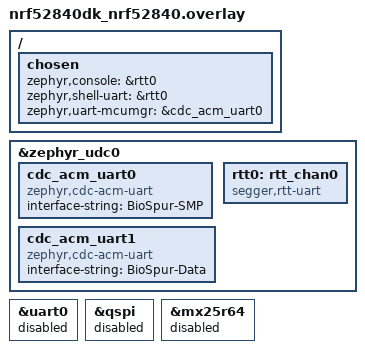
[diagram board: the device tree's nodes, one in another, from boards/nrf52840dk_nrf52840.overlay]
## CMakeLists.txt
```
cmake_minimum_required(VERSION 3.20.0)

find_package(Zephyr REQUIRED HINTS $ENV{ZEPHYR_BASE})
project(central)

target_sources(app PRIVATE
	src/main.c
	src/app_ble.c
	src/cdc_async.c
	src/ota_bridge.c
	src/tsync_master.c
	src/wdt_monitor.c
)

target_compile_definitions(app PRIVATE
	BSGR_CENTRAL_SAFE_BOOT=1
)

target_include_directories(app PRIVATE
	${CMAKE_CURRENT_SOURCE_DIR}/include
	${CMAKE_CURRENT_SOURCE_DIR}/../shared/include
)
```

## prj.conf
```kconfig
CONFIG_BT=y
CONFIG_BT_CENTRAL=y
CONFIG_BT_PERIPHERAL=n
CONFIG_BT_DEVICE_NAME="BSGR_CENTRAL"
CONFIG_BT_SMP=y
CONFIG_BT_PRIVACY=y
CONFIG_BT_BONDABLE=y
CONFIG_BT_SETTINGS=y
CONFIG_BT_GATT_CLIENT=y
CONFIG_BT_GATT_DM=y
CONFIG_BT_DFU_SMP=y
CONFIG_BT_GATT_SERVICE_CHANGED=y
CONFIG_BT_SCAN=y
CONFIG_BT_NUS_CLIENT=y
CONFIG_BT_NUS=n
CONFIG_BT_MAX_CONN=4
CONFIG_BT_MAX_PAIRED=4
CONFIG_BT_CTLR_PHY_2M=y
CONFIG_BT_USER_PHY_UPDATE=y
CONFIG_BT_CTLR_DATA_LENGTH_MAX=251
CONFIG_BT_L2CAP_TX_MTU=247
CONFIG_BT_BUF_ACL_RX_SIZE=251
CONFIG_BT_BUF_ACL_TX_SIZE=251
CONFIG_BT_BUF_ACL_RX_COUNT=16
CONFIG_BT_BUF_ACL_TX_COUNT=16
CONFIG_BT_L2CAP_TX_BUF_COUNT=16
CONFIG_BT_BUF_CMD_TX_COUNT=8
CONFIG_BT_BUF_EVT_RX_SIZE=255
CONFIG_BT_BUF_EVT_RX_COUNT=16

CONFIG_BOOTLOADER_MCUBOOT=y
CONFIG_MCUBOOT_BOOTUTIL_LIB=y
CONFIG_MCUBOOT_IMGTOOL_SIGN_VERSION="0.1.0+1"
CONFIG_FLASH=y
CONFIG_FLASH_PAGE_LAYOUT=y
CONFIG_FLASH_MAP=y
CONFIG_STREAM_FLASH=y
CONFIG_IMG_MANAGER=y
CONFIG_MCUMGR=y
CONFIG_MCUMGR_GRP_IMG=y
CONFIG_MCUMGR_GRP_OS=y
CONFIG_MCUMGR_GRP_OS_BOOTLOADER_INFO=y
CONFIG_MCUMGR_GRP_OS_MCUMGR_PARAMS=y
CONFIG_MCUMGR_TRANSPORT_UART=y
CONFIG_MCUMGR_TRANSPORT_UART_MTU=256
CONFIG_ZCBOR=y
CONFIG_ZCBOR_STOP_ON_ERROR=y
CONFIG_CRC=y
CONFIG_NET_BUF=y
CONFIG_BASE64=y

CONFIG_USB_DEVICE_STACK=y
CONFIG_USB_DEVICE_INITIALIZE_AT_BOOT=y
CONFIG_USB_CDC_ACM=y
CONFIG_USB_DEVICE_MANUFACTURER="BioSpur"
CONFIG_USB_DEVICE_PRODUCT="BioSpur Central"
CONFIG_UART_LINE_CTRL=y
CONFIG_UART_INTERRUPT_DRIVEN=y
CONFIG_SERIAL=y

CONFIG_SETTINGS=y
CONFIG_REBOOT=y
CONFIG_WATCHDOG=y
CONFIG_GPIO=y
CONFIG_ASSERT=y

CONFIG_LOG=y
CONFIG_LOG_DEFAULT_LEVEL=3
CONFIG_LOG_MODE_DEFERRED=y
CONFIG_LOG_BACKEND_RTT=y
CONFIG_LOG_BACKEND_UART=n
CONFIG_USE_SEGGER_RTT=y
CONFIG_RTT_CONSOLE=y
CONFIG_CONSOLE=y
CONFIG_UART_CONSOLE=n
CONFIG_PRINTK=y
CONFIG_SHELL=n

CONFIG_MAIN_STACK_SIZE=4096
CONFIG_SYSTEM_WORKQUEUE_STACK_SIZE=4096
CONFIG_ISR_STACK_SIZE=2048
CONFIG_HEAP_MEM_POOL_SIZE=16384
```

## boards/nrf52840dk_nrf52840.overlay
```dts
/ {
	chosen {
		zephyr,console = &rtt0;
		zephyr,shell-uart = &rtt0;
		/* Logical USB CDC interface 0 is reserved for MCUmgr/SMP. */
		zephyr,uart-mcumgr = &cdc_acm_uart0;
	};
};

&zephyr_udc0 {
	cdc_acm_uart0: cdc_acm_uart0 {
		compatible = "zephyr,cdc-acm-uart";
		/* Interface 0: MCUmgr/SMP control plane. */
		interface-string = "BioSpur-SMP";
		status = "okay";
	};

	cdc_acm_uart1: cdc_acm_uart1 {
		compatible = "zephyr,cdc-acm-uart";
		/* Interface 1: sensor/runtime data plane. */
		interface-string = "BioSpur-Data";
		status = "okay";
	};

	rtt0: rtt_chan0 {
		compatible = "segger,rtt-uart";
		status = "okay";
	};
};

&uart0 {
	status = "disabled";
};

&qspi {
	status = "disabled";
};

&mx25r64 {
	status = "disabled";
};
```

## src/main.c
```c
#include <zephyr/kernel.h>
#include <zephyr/logging/log.h>

#include "app_ble.h"
#include "cdc_async.h"
#include "ota_bridge.h"
#include "tsync_master.h"
#include "wdt_monitor.h"

LOG_MODULE_REGISTER(central_main, LOG_LEVEL_INF);

int main(void)
{
	int err;

	LOG_INF("BSGR Central safe-boot bring-up");

	err = cdc_async_init();
	if (err != 0) {
		LOG_ERR("cdc_async_init failed: %d", err);
		return err;
	}

	/* Give USB CDC enumeration a quiet window before optional subsystems. */
	k_sleep(K_MSEC(800));

	err = wdt_monitor_init();
	if (err != 0) {
		return err;
	}

#if !defined(BSGR_CENTRAL_SAFE_BOOT) || (BSGR_CENTRAL_SAFE_BOOT == 0)
	tsync_master_init();

	err = app_ble_init();
	if (err != 0) {
		LOG_ERR("app_ble_init failed: %d", err);
		return err;
	}

	err = ota_bridge_init();
	if (err != 0) {
		LOG_ERR("ota_bridge_init failed: %d", err);
		return err;
	}

	err = app_ble_start_scan();
	if (err != 0) {
		LOG_WRN("app_ble_start_scan degraded: %d", err);
	}
#else
	LOG_WRN("BSGR_CENTRAL_SAFE_BOOT active: BLE/bridge/tsync deferred");
#endif

	while (1) {
#if !defined(BSGR_CENTRAL_SAFE_BOOT) || (BSGR_CENTRAL_SAFE_BOOT == 0)
		ota_bridge_process();
		app_ble_process();
#endif
		wdt_monitor_feed();
		k_sleep(K_MSEC(20));
	}

	return 0;
}
```

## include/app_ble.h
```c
#ifndef BSGR_CENTRAL_APP_BLE_H_
#define BSGR_CENTRAL_APP_BLE_H_

#include <stddef.h>
#include <stdbool.h>
#include <stdint.h>

#include <zephyr/bluetooth/addr.h>
#include <zephyr/bluetooth/conn.h>
#include <zephyr/kernel.h>
#include <zephyr/mgmt/mcumgr/mgmt/mgmt_defines.h>

#include <bluetooth/services/nus_client.h>

#define BSGR_IMG_HASH_LEN 32
#define BSGR_IMG_VER_MAX_STR_LEN (sizeof("255.255.65535.4294967295"))

struct bsgr_mcumgr_image_list_flags {
	bool bootable : 1;
	bool pending : 1;
	bool confirmed : 1;
	bool active : 1;
	bool permanent : 1;
};

struct bsgr_mcumgr_image_data {
	uint32_t slot_num;
	uint32_t img_num;
	char hash[BSGR_IMG_HASH_LEN];
	char version[BSGR_IMG_VER_MAX_STR_LEN + 1];
	struct bsgr_mcumgr_image_list_flags flags;
};

struct bsgr_mcumgr_image_state {
	enum mcumgr_err_t status;
	int image_list_length;
	struct bsgr_mcumgr_image_data *image_list;
};

struct bsgr_central_peer {
	bool in_use;
	bool identified;
	uint16_t device_id;
	uint16_t last_seq;
	int8_t rssi;
	uint32_t last_seen_ticks;
	bt_addr_le_t addr;
	struct bt_conn *conn;
	struct bt_nus_client nus_client;
};

int app_ble_init(void);
int app_ble_start_scan(void);
int app_ble_stop_scan(void);
void app_ble_process(void);
const struct bsgr_central_peer *app_ble_peers_get(size_t *count);
int app_ble_ota_connect(const char *target_name, k_timeout_t timeout);
void app_ble_ota_disconnect(void);
bool app_ble_ota_ready(void);
int app_ble_ota_upload_start(size_t image_size);
int app_ble_ota_upload_chunk(const uint8_t *data, size_t len, size_t *remote_offset);
int app_ble_ota_read_images(struct bsgr_mcumgr_image_state *res_buf,
			    struct bsgr_mcumgr_image_data *image_list,
			    size_t image_list_size);
int app_ble_ota_mark_test(const char *hash);
int app_ble_ota_reset_target(void);
const char *app_ble_ota_target_name(void);

#endif /* BSGR_CENTRAL_APP_BLE_H_ */
```

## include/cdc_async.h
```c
#ifndef BSGR_CENTRAL_CDC_ASYNC_H_
#define BSGR_CENTRAL_CDC_ASYNC_H_

#include <stddef.h>
#include <stdbool.h>
#include <stdint.h>

enum bsgr_cdc_channel {
	BSGR_CDC_CHANNEL_MCUMGR = 0,
	BSGR_CDC_CHANNEL_DATA = 1,
	BSGR_CDC_CHANNEL_COUNT = 2,
};

int cdc_async_init(void);
bool cdc_async_ready(void);
int cdc_async_write(enum bsgr_cdc_channel channel, const uint8_t *data, size_t len);
int cdc_async_write_data(const uint8_t *data, size_t len);
int cdc_async_poll_in(enum bsgr_cdc_channel channel, uint8_t *ch);

#endif /* BSGR_CENTRAL_CDC_ASYNC_H_ */
```

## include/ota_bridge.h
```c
#ifndef BSGR_CENTRAL_OTA_BRIDGE_H_
#define BSGR_CENTRAL_OTA_BRIDGE_H_

int ota_bridge_init(void);
void ota_bridge_process(void);

#endif /* BSGR_CENTRAL_OTA_BRIDGE_H_ */
```

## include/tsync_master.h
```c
#ifndef BSGR_CENTRAL_TSYNC_MASTER_H_
#define BSGR_CENTRAL_TSYNC_MASTER_H_

#include <stdint.h>

#include "bsgr_protocol.h"

struct bsgr_tsync_master_state {
	int64_t epoch_ms;
	uint16_t session_id;
	uint16_t request_id;
};

void tsync_master_init(void);
void tsync_master_set_epoch_ms(int64_t epoch_ms);
int64_t tsync_master_get_epoch_ms(void);
uint16_t tsync_master_next_request_id(void);
uint16_t tsync_master_get_session_id(void);
void tsync_master_fill_payload(struct bsgr_tsync_payload *payload, uint32_t reference_ticks);

#endif /* BSGR_CENTRAL_TSYNC_MASTER_H_ */
```

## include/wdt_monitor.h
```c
#ifndef BSGR_CENTRAL_WDT_MONITOR_H_
#define BSGR_CENTRAL_WDT_MONITOR_H_

int wdt_monitor_init(void);
void wdt_monitor_feed(void);

#endif /* BSGR_CENTRAL_WDT_MONITOR_H_ */
```

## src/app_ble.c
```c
#include <errno.h>
#include <stdio.h>
#include <string.h>

#include <zcbor_common.h>
#include <zcbor_decode.h>
#include <zcbor_encode.h>

#include <zephyr/bluetooth/bluetooth.h>
#include <zephyr/bluetooth/conn.h>
#include <zephyr/bluetooth/gatt.h>
#include <zephyr/bluetooth/hci.h>
#include <zephyr/logging/log.h>
#include <zephyr/settings/settings.h>
#include <zephyr/sys/byteorder.h>
#include <zephyr/sys/util.h>

#include <bluetooth/gatt_dm.h>
#include <bluetooth/services/dfu_smp.h>

#include <mgmt/mcumgr/util/zcbor_bulk.h>

#include <zephyr/mgmt/mcumgr/grp/os_mgmt/os_mgmt.h>
#include <zephyr/mgmt/mcumgr/mgmt/mgmt_defines.h>

#include "app_ble.h"
#include "bsgr_protocol.h"
#include "cdc_async.h"

LOG_MODULE_REGISTER(central_app_ble, LOG_LEVEL_INF);

#define BSGR_CENTRAL_MAX_PEERS 4
#define BSGR_SCAN_INTERVAL 0x0060
#define BSGR_SCAN_WINDOW 0x0030
#define BSGR_OTA_NAME_MAX 31
#define BSGR_OTA_RSP_BUFFER_SIZE 768
#define BSGR_OTA_DEFAULT_TIMEOUT K_SECONDS(20)
#define BSGR_IMG_MGMT_ID_STATE 0
#define BSGR_IMG_MGMT_ID_UPLOAD 1

struct bsgr_smp_message {
	struct bt_dfu_smp_header header;
	uint8_t payload[BSGR_OTA_RSP_BUFFER_SIZE - sizeof(struct bt_dfu_smp_header)];
};

struct bsgr_ota_state {
	struct bt_conn *conn;
	struct bt_dfu_smp dfu_smp;
	struct bt_gatt_exchange_params exchange_params;
	struct k_sem connect_sem;
	struct k_sem rsp_sem;
	char target_name[BSGR_OTA_NAME_MAX + 1];
	struct bsgr_smp_message rsp_msg;
	size_t rsp_total_size;
	size_t upload_size;
	size_t upload_offset;
	int connect_status;
	int rsp_status;
	bool connect_requested;
	bool dfu_ready;
	bool discovery_pending;
	bool connect_waiting;
	bool scan_paused;
};

static struct bsgr_central_peer peers[BSGR_CENTRAL_MAX_PEERS];
static bool scan_running;
static struct bsgr_ota_state ota_state;

static struct bsgr_central_peer *peer_lookup_by_nus(struct bt_nus_client *nus)
{
	size_t i;

	for (i = 0; i < ARRAY_SIZE(peers); ++i) {
		if (&peers[i].nus_client == nus) {
			return &peers[i];
		}
	}

	return NULL;
}

static struct bsgr_central_peer *peer_alloc_from_addr(const bt_addr_le_t *addr)
{
	size_t i;

	for (i = 0; i < ARRAY_SIZE(peers); ++i) {
		if (peers[i].in_use && (bt_addr_le_cmp(&peers[i].addr, addr) == 0)) {
			return &peers[i];
		}
	}

	for (i = 0; i < ARRAY_SIZE(peers); ++i) {
		if (!peers[i].in_use) {
			memset(&peers[i], 0, sizeof(peers[i]));
			peers[i].in_use = true;
			bt_addr_le_copy(&peers[i].addr, addr);
			return &peers[i];
		}
	}

	return NULL;
}

static void peer_release(struct bt_conn *conn)
{
	size_t i;

	for (i = 0; i < ARRAY_SIZE(peers); ++i) {
		if (peers[i].conn == conn) {
			if (peers[i].conn != NULL) {
				bt_conn_unref(peers[i].conn);
			}
			memset(&peers[i], 0, sizeof(peers[i]));
			return;
		}
	}
}

static void forward_frame_summary(const struct bsgr_frame_header *hdr)
{
	char line[96];
	int len;

	len = snprintf(line, sizeof(line), "dev=%u type=0x%02x seq=%u len=%u\r\n",
		       hdr->device_id, hdr->frame_type, hdr->seq, hdr->payload_len);
	if (len > 0) {
		(void)cdc_async_write_data((const uint8_t *)line, MIN((size_t)len, sizeof(line)));
	}
}

static uint8_t nus_recv_cb(struct bt_nus_client *nus, const uint8_t *data, uint16_t len)
{
	const struct bsgr_frame_header *hdr;
	struct bsgr_central_peer *peer = peer_lookup_by_nus(nus);

	if ((peer == NULL) || (len < sizeof(*hdr))) {
		return BT_GATT_ITER_CONTINUE;
	}

	hdr = (const struct bsgr_frame_header *)data;
	if (!bsgr_frame_header_is_valid(hdr)) {
		return BT_GATT_ITER_CONTINUE;
	}

	peer->identified = true;
	peer->device_id = hdr->device_id;
	peer->last_seq = hdr->seq;
	peer->last_seen_ticks = k_uptime_ticks();
	forward_frame_summary(hdr);

	return BT_GATT_ITER_CONTINUE;
}

static void nus_sent_cb(struct bt_nus_client *nus, uint8_t err,
			const uint8_t *data, uint16_t len)
{
	ARG_UNUSED(nus);
	ARG_UNUSED(err);
	ARG_UNUSED(data);
	ARG_UNUSED(len);
}

static const struct bt_nus_client_init_param nus_init_param = {
	.cb = {
		.received = nus_recv_cb,
		.sent = nus_sent_cb,
	},
};

static uint16_t ota_rsp_payload_len(const struct bt_dfu_smp_header *hdr)
{
	return ((uint16_t)hdr->len_h8 << 8) | hdr->len_l8;
}

static uint16_t ota_rsp_group(const struct bt_dfu_smp_header *hdr)
{
	return ((uint16_t)hdr->group_h8 << 8) | hdr->group_l8;
}

static void ota_rsp_part_cb(struct bt_dfu_smp *dfu_smp)
{
	const struct bt_dfu_smp_rsp_state *rsp_state = bt_dfu_smp_rsp_state(dfu_smp);
	uint8_t *dst = (uint8_t *)&ota_state.rsp_msg;

	if ((rsp_state->offset + rsp_state->chunk_size) > sizeof(ota_state.rsp_msg)) {
		ota_state.rsp_status = -EMSGSIZE;
		k_sem_give(&ota_state.rsp_sem);
		return;
	}

	memcpy(dst + rsp_state->offset, rsp_state->data, rsp_state->chunk_size);
	ota_state.rsp_total_size = rsp_state->total_size;

	if (bt_dfu_smp_rsp_total_check(dfu_smp)) {
		k_sem_give(&ota_state.rsp_sem);
	}
}

static void ota_error_cb(struct bt_dfu_smp *dfu_smp, int err)
{
	ARG_UNUSED(dfu_smp);
	ota_state.rsp_status = err;
	k_sem_give(&ota_state.rsp_sem);
}

static const struct bt_dfu_smp_init_params ota_dfu_init_params = {
	.error_cb = ota_error_cb,
};

static void ota_reset_response_state(void)
{
	memset(&ota_state.rsp_msg, 0, sizeof(ota_state.rsp_msg));
	ota_state.rsp_total_size = 0U;
	ota_state.rsp_status = 0;
	k_sem_reset(&ota_state.rsp_sem);
}

static int ota_send_command(uint8_t op, uint16_t group, uint8_t id,
			    const uint8_t *payload, size_t payload_len,
			    k_timeout_t timeout)
{
	struct {
		struct bt_dfu_smp_header header;
		uint8_t payload[320];
	} cmd;
	int err;

	if (!ota_state.dfu_ready || (ota_state.conn == NULL)) {
		return -ENOTCONN;
	}

	if (payload_len > sizeof(cmd.payload)) {
		return -EMSGSIZE;
	}

	memset(&cmd, 0, sizeof(cmd));
	cmd.header.op = op;
	cmd.header.flags = 0U;
	cmd.header.len_h8 = (uint8_t)((payload_len >> 8) & 0xFF);
	cmd.header.len_l8 = (uint8_t)(payload_len & 0xFF);
	cmd.header.group_h8 = (uint8_t)((group >> 8) & 0xFF);
	cmd.header.group_l8 = (uint8_t)(group & 0xFF);
	cmd.header.id = id;
	if ((payload != NULL) && (payload_len > 0U)) {
		memcpy(cmd.payload, payload, payload_len);
	}

	ota_reset_response_state();
	err = bt_dfu_smp_command(&ota_state.dfu_smp, ota_rsp_part_cb,
				 sizeof(cmd.header) + payload_len, &cmd);
	if (err != 0) {
		return err;
	}

	if (k_sem_take(&ota_state.rsp_sem, timeout) != 0) {
		return -ETIMEDOUT;
	}

	return ota_state.rsp_status;
}

static int ota_decode_image_state(struct bsgr_mcumgr_image_state *res_buf,
				  struct bsgr_mcumgr_image_data *image_list,
				  size_t image_list_size)
{
	zcbor_state_t zsd[CONFIG_MCUMGR_SMP_CBOR_MAX_DECODING_LEVELS + 2];
	struct zcbor_string value = {0};
	struct zcbor_string hash = {0};
	struct zcbor_string version = {0};
	bool bootable = false;
	bool pending = false;
	bool confirmed = false;
	bool active = false;
	bool permanent = false;
	bool ok;
	int rc = 0;
	size_t decoded;
	size_t count = 0U;
	uint32_t img_num;
	uint32_t slot_num;
	uint8_t *payload;
	size_t payload_len;

	if ((res_buf == NULL) || (image_list == NULL) || (image_list_size == 0U)) {
		return -EINVAL;
	}

	payload = ota_state.rsp_msg.payload;
	payload_len = ota_rsp_payload_len(&ota_state.rsp_msg.header);
	memset(res_buf, 0, sizeof(*res_buf));
	res_buf->image_list = image_list;

	if ((ota_state.rsp_msg.header.op != MGMT_OP_READ_RSP) &&
	    (ota_state.rsp_msg.header.op != MGMT_OP_WRITE_RSP)) {
		res_buf->status = MGMT_ERR_ECORRUPT;
		return -EBADMSG;
	}

	if (ota_rsp_group(&ota_state.rsp_msg.header) != MGMT_GROUP_ID_IMAGE) {
		res_buf->status = MGMT_ERR_ECORRUPT;
		return -EBADMSG;
	}

	zcbor_new_decode_state(zsd, ARRAY_SIZE(zsd), payload, payload_len, 1, NULL, 0);
	ok = zcbor_map_start_decode(zsd);
	if (!ok) {
		res_buf->status = MGMT_ERR_ECORRUPT;
		return -EBADMSG;
	}

	ok = zcbor_tstr_decode(zsd, &value);
	if (!ok || (value.len != 6U) || (memcmp(value.value, "images", 6U) != 0)) {
		res_buf->status = MGMT_ERR_EINVAL;
		return -EBADMSG;
	}

	ok = zcbor_list_start_decode(zsd);
	if (!ok) {
		res_buf->status = MGMT_ERR_ECORRUPT;
		return -EBADMSG;
	}

	while ((count < image_list_size) && (rc == 0)) {
		struct zcbor_map_decode_key_val decode_map[] = {
			ZCBOR_MAP_DECODE_KEY_DECODER("version", zcbor_tstr_decode, &version),
			ZCBOR_MAP_DECODE_KEY_DECODER("hash", zcbor_bstr_decode, &hash),
			ZCBOR_MAP_DECODE_KEY_DECODER("slot", zcbor_uint32_decode, &slot_num),
			ZCBOR_MAP_DECODE_KEY_DECODER("image", zcbor_uint32_decode, &img_num),
			ZCBOR_MAP_DECODE_KEY_DECODER("bootable", zcbor_bool_decode, &bootable),
			ZCBOR_MAP_DECODE_KEY_DECODER("pending", zcbor_bool_decode, &pending),
			ZCBOR_MAP_DECODE_KEY_DECODER("confirmed", zcbor_bool_decode, &confirmed),
			ZCBOR_MAP_DECODE_KEY_DECODER("active", zcbor_bool_decode, &active),
			ZCBOR_MAP_DECODE_KEY_DECODER("permanent", zcbor_bool_decode, &permanent),
		};

		bootable = false;
		pending = false;
		confirmed = false;
		active = false;
		permanent = false;
		img_num = 0U;
		slot_num = UINT32_MAX;
		hash.len = 0U;
		version.len = 0U;
		zcbor_map_decode_bulk_reset(decode_map, ARRAY_SIZE(decode_map));
		rc = zcbor_map_decode_bulk(zsd, decode_map, ARRAY_SIZE(decode_map), &decoded);
		if (rc != 0) {
			break;
		}

		if ((hash.len != BSGR_IMG_HASH_LEN) || (version.len == 0U)) {
			res_buf->status = MGMT_ERR_EINVAL;
			return -EBADMSG;
		}

		image_list[count].img_num = img_num;
		image_list[count].slot_num = slot_num;
		memcpy(image_list[count].hash, hash.value, BSGR_IMG_HASH_LEN);
		if (version.len > BSGR_IMG_VER_MAX_STR_LEN) {
			version.len = BSGR_IMG_VER_MAX_STR_LEN;
		}
		memcpy(image_list[count].version, version.value, version.len);
		image_list[count].version[version.len] = '\0';
		image_list[count].flags.bootable = bootable;
		image_list[count].flags.pending = pending;
		image_list[count].flags.confirmed = confirmed;
		image_list[count].flags.active = active;
		image_list[count].flags.permanent = permanent;
		count++;
	}

	ok = zcbor_list_end_decode(zsd);
	if (!ok) {
		res_buf->status = MGMT_ERR_ECORRUPT;
		return -EBADMSG;
	}

	res_buf->image_list_length = (int)count;
	res_buf->status = MGMT_ERR_EOK;
	return 0;
}

static int ota_decode_upload_offset(size_t *offset_out)
{
	zcbor_state_t zsd[CONFIG_MCUMGR_SMP_CBOR_MAX_DECODING_LEVELS + 2];
	int32_t rc_value = MGMT_ERR_EOK;
	struct zcbor_map_decode_key_val decode_map[] = {
		ZCBOR_MAP_DECODE_KEY_DECODER("off", zcbor_size_decode, offset_out),
		ZCBOR_MAP_DECODE_KEY_DECODER("rc", zcbor_int32_decode, &rc_value),
	};
	size_t decoded;
	size_t offset = SIZE_MAX;
	size_t payload_len;

	payload_len = ota_rsp_payload_len(&ota_state.rsp_msg.header);
	zcbor_new_decode_state(zsd, ARRAY_SIZE(zsd), ota_state.rsp_msg.payload,
			       payload_len, 1, NULL, 0);
	*offset_out = offset;
	if (zcbor_map_decode_bulk(zsd, decode_map, ARRAY_SIZE(decode_map), &decoded) != 0) {
		return -EBADMSG;
	}

	if ((*offset_out == SIZE_MAX) || (rc_value != MGMT_ERR_EOK)) {
		return -EIO;
	}

	return 0;
}

static int ota_find_secondary_hash(char *hash_out)
{
	struct bsgr_mcumgr_image_data images[4];
	struct bsgr_mcumgr_image_state state;
	size_t i;
	int err;

	err = app_ble_ota_read_images(&state, images, ARRAY_SIZE(images));
	if (err != 0) {
		return err;
	}

	for (i = 0; i < (size_t)state.image_list_length; ++i) {
		if (images[i].slot_num != 0U) {
			memcpy(hash_out, images[i].hash, BSGR_IMG_HASH_LEN);
			return 0;
		}
	}

	return -ENOENT;
}

static void discovery_completed_cb(struct bt_gatt_dm *dm, void *context)
{
	int err;

	ARG_UNUSED(context);

	err = bt_dfu_smp_handles_assign(dm, &ota_state.dfu_smp);
	if (err != 0) {
		ota_state.connect_status = err;
	} else {
		ota_state.dfu_ready = true;
		ota_state.connect_status = 0;
	}

	ota_state.discovery_pending = false;
	(void)bt_gatt_dm_data_release(dm);
	k_sem_give(&ota_state.connect_sem);
}

static void discovery_service_not_found_cb(struct bt_conn *conn, void *context)
{
	ARG_UNUSED(conn);
	ARG_UNUSED(context);
	ota_state.connect_status = -ENOTSUP;
	ota_state.discovery_pending = false;
	k_sem_give(&ota_state.connect_sem);
}

static void discovery_error_found_cb(struct bt_conn *conn, int err, void *context)
{
	ARG_UNUSED(conn);
	ARG_UNUSED(context);
	ota_state.connect_status = err;
	ota_state.discovery_pending = false;
	k_sem_give(&ota_state.connect_sem);
}

static const struct bt_gatt_dm_cb ota_discovery_cb = {
	.completed = discovery_completed_cb,
	.service_not_found = discovery_service_not_found_cb,
	.error_found = discovery_error_found_cb,
};

static void exchange_func(struct bt_conn *conn, uint8_t err,
			  struct bt_gatt_exchange_params *params)
{
	ARG_UNUSED(conn);
	ARG_UNUSED(params);
	if (err != 0U) {
		LOG_WRN("MTU exchange failed: %u", err);
	}
}

static void connected(struct bt_conn *conn, uint8_t err)
{
	const bt_addr_le_t *dst = bt_conn_get_dst(conn);
	struct bsgr_central_peer *peer;
	int rc;

	if ((err != 0U) || (dst == NULL)) {
		if (ota_state.connect_waiting) {
			ota_state.connect_status = -ECONNREFUSED;
			k_sem_give(&ota_state.connect_sem);
		}
		return;
	}

	peer = peer_alloc_from_addr(dst);
	if (peer != NULL) {
		peer->conn = bt_conn_ref(conn);
		peer->last_seen_ticks = k_uptime_ticks();
	}

	if ((ota_state.conn != NULL) && (conn == ota_state.conn) && ota_state.connect_waiting) {
		ota_state.exchange_params.func = exchange_func;
		(void)bt_gatt_exchange_mtu(conn, &ota_state.exchange_params);
		ota_state.discovery_pending = true;
		rc = bt_gatt_dm_start(conn, BT_UUID_DFU_SMP_SERVICE, &ota_discovery_cb, NULL);
		if (rc != 0) {
			ota_state.discovery_pending = false;
			ota_state.connect_status = rc;
			k_sem_give(&ota_state.connect_sem);
		}
	}
}

static void disconnected(struct bt_conn *conn, uint8_t reason)
{
	LOG_INF("Peer disconnected: 0x%02x", reason);
	if ((ota_state.conn != NULL) && (conn == ota_state.conn)) {
		bt_conn_unref(ota_state.conn);
		ota_state.conn = NULL;
		ota_state.dfu_ready = false;
		ota_state.discovery_pending = false;
		if (ota_state.connect_waiting) {
			ota_state.connect_status = -ENOTCONN;
			k_sem_give(&ota_state.connect_sem);
		}
	}

	peer_release(conn);
}

BT_CONN_CB_DEFINE(central_conn_callbacks) = {
	.connected = connected,
	.disconnected = disconnected,
};

static bool scan_data_name_matches(struct bt_data *data, void *user_data)
{
	char *name = user_data;
	size_t copy_len;

	if ((data->type != BT_DATA_NAME_COMPLETE) && (data->type != BT_DATA_NAME_SHORTENED)) {
		return true;
	}

	copy_len = MIN((size_t)data->data_len, (size_t)BSGR_OTA_NAME_MAX);
	memcpy(name, data->data, copy_len);
	name[copy_len] = '\0';
	return false;
}

static bool ad_name_has_bsgr_prefix(struct net_buf_simple *ad)
{
	return (ad != NULL) && (ad->len >= 4U) && (ad->data[0] == 'B');
}

static bool scan_data_cb(struct bt_data *data, void *user_data)
{
	bool *matched = user_data;

	if ((data->type == BT_DATA_NAME_COMPLETE) || (data->type == BT_DATA_NAME_SHORTENED)) {
		struct net_buf_simple ad = {
			.data = data->data,
			.len = data->data_len,
			.size = data->data_len,
		};

		if (ad_name_has_bsgr_prefix(&ad)) {
			*matched = true;
			return false;
		}
	}

	return true;
}

static void device_found(const bt_addr_le_t *addr, int8_t rssi, uint8_t type,
			 struct net_buf_simple *ad)
{
	bool matched = false;
	char adv_name[BSGR_OTA_NAME_MAX + 1] = {0};
	int err;

	bt_data_parse(ad, scan_data_cb, &matched);
	if (matched) {
		LOG_INF("Discovered BSGR candidate RSSI %d", rssi);
	}

	if (!ota_state.connect_requested || (ota_state.conn != NULL)) {
		return;
	}

	bt_data_parse(ad, scan_data_name_matches, adv_name);
	if ((adv_name[0] == '\0') || (strcmp(adv_name, ota_state.target_name) != 0)) {
		return;
	}

	(void)app_ble_stop_scan();
	err = bt_conn_le_create(addr, BT_CONN_LE_CREATE_CONN, BT_LE_CONN_PARAM_DEFAULT,
				&ota_state.conn);
	if (err != 0) {
		ota_state.connect_status = err;
		ota_state.connect_requested = false;
		k_sem_give(&ota_state.connect_sem);
	}
}

int app_ble_init(void)
{
	int err;
	size_t i;

	err = bt_enable(NULL);
	if (err != 0) {
		return err;
	}

	if (IS_ENABLED(CONFIG_SETTINGS)) {
		settings_load();
	}

	memset(peers, 0, sizeof(peers));
	memset(&ota_state, 0, sizeof(ota_state));
	k_sem_init(&ota_state.connect_sem, 0, 1);
	k_sem_init(&ota_state.rsp_sem, 0, 1);
	err = bt_dfu_smp_init(&ota_state.dfu_smp, &ota_dfu_init_params);
	if (err != 0) {
		return err;
	}

	for (i = 0; i < ARRAY_SIZE(peers); ++i) {
		err = bt_nus_client_init(&peers[i].nus_client, &nus_init_param);
		if (err != 0) {
			return err;
		}
	}

	LOG_INF("BSGR Central BLE framework initialized");
	return 0;
}

int app_ble_start_scan(void)
{
	struct bt_le_scan_param scan_param = {
		.type = BT_LE_SCAN_TYPE_ACTIVE,
		.options = BT_LE_SCAN_OPT_NONE,
		.interval = BSGR_SCAN_INTERVAL,
		.window = BSGR_SCAN_WINDOW,
	};
	int err;

	err = bt_le_scan_start(&scan_param, device_found);
	if ((err == -EALREADY) || (err == 0)) {
		scan_running = true;
		return 0;
	}

	return err;
}

int app_ble_stop_scan(void)
{
	int err;

	err = bt_le_scan_stop();
	if ((err == -EALREADY) || (err == 0)) {
		scan_running = false;
		return 0;
	}

	return err;
}

void app_ble_process(void)
{
	size_t i;

	for (i = 0; i < ARRAY_SIZE(peers); ++i) {
		if (peers[i].identified) {
			peers[i].rssi = 0;
		}
	}

	if (!scan_running && !ota_state.connect_requested && (ota_state.conn == NULL)) {
		(void)app_ble_start_scan();
	}
}

const struct bsgr_central_peer *app_ble_peers_get(size_t *count)
{
	if (count != NULL) {
		*count = ARRAY_SIZE(peers);
	}

	return peers;
}

int app_ble_ota_connect(const char *target_name, k_timeout_t timeout)
{
	int err;

	if ((target_name == NULL) || (target_name[0] == '\0')) {
		return -EINVAL;
	}

	if (ota_state.dfu_ready && (strcmp(ota_state.target_name, target_name) == 0)) {
		return 0;
	}

	app_ble_ota_disconnect();
	memset(ota_state.target_name, 0, sizeof(ota_state.target_name));
	strncpy(ota_state.target_name, target_name, sizeof(ota_state.target_name) - 1U);
	ota_state.connect_status = 0;
	ota_state.connect_requested = true;
	ota_state.connect_waiting = true;
	k_sem_reset(&ota_state.connect_sem);

	err = app_ble_start_scan();
	if ((err != 0) && (err != -EALREADY)) {
		ota_state.connect_requested = false;
		ota_state.connect_waiting = false;
		return err;
	}

	if (k_sem_take(&ota_state.connect_sem, timeout) != 0) {
		ota_state.connect_requested = false;
		ota_state.connect_waiting = false;
		return -ETIMEDOUT;
	}

	ota_state.connect_requested = false;
	ota_state.connect_waiting = false;
	return ota_state.connect_status;
}

void app_ble_ota_disconnect(void)
{
	ota_state.connect_requested = false;
	ota_state.connect_waiting = false;
	ota_state.dfu_ready = false;
	ota_state.discovery_pending = false;
	ota_state.upload_offset = 0U;
	ota_state.upload_size = 0U;
	if (ota_state.conn != NULL) {
		bt_conn_disconnect(ota_state.conn, BT_HCI_ERR_REMOTE_USER_TERM_CONN);
		bt_conn_unref(ota_state.conn);
		ota_state.conn = NULL;
	}
}

bool app_ble_ota_ready(void)
{
	return ota_state.dfu_ready && (ota_state.conn != NULL);
}

int app_ble_ota_upload_start(size_t image_size)
{
	if (!app_ble_ota_ready() || (image_size == 0U)) {
		return -EINVAL;
	}

	ota_state.upload_size = image_size;
	ota_state.upload_offset = 0U;
	return 0;
}

int app_ble_ota_upload_chunk(const uint8_t *data, size_t len, size_t *remote_offset)
{
	zcbor_state_t zse[CONFIG_MCUMGR_SMP_CBOR_MAX_DECODING_LEVELS + 2];
	uint8_t payload[256];
	bool ok;
	int err;
	size_t payload_len;
	size_t rsp_offset = SIZE_MAX;

	if (!app_ble_ota_ready() || (data == NULL) || (len == 0U)) {
		return -EINVAL;
	}

	if (len > 128U) {
		return -EMSGSIZE;
	}

	zcbor_new_encode_state(zse, ARRAY_SIZE(zse), payload, sizeof(payload), 0);
	ok = zcbor_map_start_encode(zse, ota_state.upload_offset == 0U ? 8 : 6) &&
	     zcbor_tstr_put_lit(zse, "image") && zcbor_uint32_put(zse, 0U) &&
	     zcbor_tstr_put_lit(zse, "data") && zcbor_bstr_encode_ptr(zse, data, len) &&
	     zcbor_tstr_put_lit(zse, "off") && zcbor_size_put(zse, ota_state.upload_offset);
	if (ok && (ota_state.upload_offset == 0U)) {
		ok = zcbor_tstr_put_lit(zse, "len") &&
		     zcbor_size_put(zse, ota_state.upload_size);
	}
	if (ok) {
		ok = zcbor_map_end_encode(zse, ota_state.upload_offset == 0U ? 8 : 6);
	}
	if (!ok) {
		return -ENOMEM;
	}

	payload_len = zse->payload - payload;
	err = ota_send_command(MGMT_OP_WRITE, MGMT_GROUP_ID_IMAGE, BSGR_IMG_MGMT_ID_UPLOAD,
			      payload, payload_len, K_SECONDS(15));
	if (err != 0) {
		return err;
	}

	err = ota_decode_upload_offset(&rsp_offset);
	if (err != 0) {
		return err;
	}

	ota_state.upload_offset = rsp_offset;
	if (remote_offset != NULL) {
		*remote_offset = rsp_offset;
	}

	return 0;
}

int app_ble_ota_read_images(struct bsgr_mcumgr_image_state *res_buf,
			    struct bsgr_mcumgr_image_data *image_list,
			    size_t image_list_size)
{
	zcbor_state_t zse[CONFIG_MCUMGR_SMP_CBOR_MAX_DECODING_LEVELS];
	uint8_t payload[16];
	bool ok;
	size_t payload_len;
	int err;

	if (!app_ble_ota_ready()) {
		return -ENOTCONN;
	}

	zcbor_new_encode_state(zse, ARRAY_SIZE(zse), payload, sizeof(payload), 0);
	ok = zcbor_map_start_encode(zse, 1) && zcbor_map_end_encode(zse, 1);
	if (!ok) {
		return -ENOMEM;
	}

	payload_len = zse->payload - payload;
	err = ota_send_command(MGMT_OP_READ, MGMT_GROUP_ID_IMAGE, BSGR_IMG_MGMT_ID_STATE,
			      payload, payload_len, BSGR_OTA_DEFAULT_TIMEOUT);
	if (err != 0) {
		return err;
	}

	return ota_decode_image_state(res_buf, image_list, image_list_size);
}

int app_ble_ota_mark_test(const char *hash)
{
	zcbor_state_t zse[CONFIG_MCUMGR_SMP_CBOR_MAX_DECODING_LEVELS];
	uint8_t payload[80];
	bool ok;
	size_t payload_len;

	if (!app_ble_ota_ready() || (hash == NULL)) {
		return -EINVAL;
	}

	zcbor_new_encode_state(zse, ARRAY_SIZE(zse), payload, sizeof(payload), 0);
	ok = zcbor_map_start_encode(zse, 4) &&
	     zcbor_tstr_put_lit(zse, "confirm") &&
	     zcbor_bool_put(zse, false) &&
	     zcbor_tstr_put_lit(zse, "hash") &&
	     zcbor_bstr_encode_ptr(zse, hash, BSGR_IMG_HASH_LEN) &&
	     zcbor_map_end_encode(zse, 4);
	if (!ok) {
		return -ENOMEM;
	}

	payload_len = zse->payload - payload;
	return ota_send_command(MGMT_OP_WRITE, MGMT_GROUP_ID_IMAGE, BSGR_IMG_MGMT_ID_STATE,
			       payload, payload_len, BSGR_OTA_DEFAULT_TIMEOUT);
}

int app_ble_ota_reset_target(void)
{
	return ota_send_command(MGMT_OP_WRITE, MGMT_GROUP_ID_OS, OS_MGMT_ID_RESET,
			       NULL, 0U, K_SECONDS(5));
}

const char *app_ble_ota_target_name(void)
{
	return ota_state.target_name;
}
```

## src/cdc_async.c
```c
#include <errno.h>
#include <stdbool.h>

#include <zephyr/device.h>
#include <zephyr/drivers/uart.h>
#include <zephyr/kernel.h>
#include <zephyr/sys/util.h>
#include <zephyr/usb/usb_device.h>

#include "cdc_async.h"

static const struct device *cdc_devices[BSGR_CDC_CHANNEL_COUNT] = {
	DEVICE_DT_GET(DT_NODELABEL(cdc_acm_uart0)),
	DEVICE_DT_GET(DT_NODELABEL(cdc_acm_uart1)),
};

static struct k_mutex cdc_lock;
static bool cdc_is_ready;

static bool cdc_channel_host_ready(enum bsgr_cdc_channel channel)
{
	uint32_t dtr = 0U;
	int err;

	if (channel >= BSGR_CDC_CHANNEL_COUNT) {
		return false;
	}

	err = uart_line_ctrl_get(cdc_devices[channel], UART_LINE_CTRL_DTR, &dtr);
	if (err == -ENOSYS) {
		return true;
	}
	if (err != 0) {
		return false;
	}

	return dtr != 0U;
}

int cdc_async_init(void)
{
	int err;
	size_t i;

	if (cdc_is_ready) {
		return 0;
	}

	for (i = 0; i < ARRAY_SIZE(cdc_devices); ++i) {
		if (!device_is_ready(cdc_devices[i])) {
			return -ENODEV;
		}
	}

	err = usb_enable(NULL);
	if ((err != 0) && (err != -EALREADY)) {
		return err;
	}

	k_mutex_init(&cdc_lock);
	cdc_is_ready = true;
	return 0;
}

bool cdc_async_ready(void)
{
	return cdc_is_ready;
}

int cdc_async_write(enum bsgr_cdc_channel channel, const uint8_t *data, size_t len)
{
	size_t i;

	if ((!cdc_is_ready) || (channel >= BSGR_CDC_CHANNEL_COUNT) || (data == NULL)) {
		return -EINVAL;
	}
	if ((len > 0U) && !cdc_channel_host_ready(channel)) {
		return -EAGAIN;
	}

	k_mutex_lock(&cdc_lock, K_FOREVER);
	for (i = 0; i < len; ++i) {
		uart_poll_out(cdc_devices[channel], data[i]);
	}
	k_mutex_unlock(&cdc_lock);

	return (int)len;
}

int cdc_async_write_data(const uint8_t *data, size_t len)
{
	return cdc_async_write(BSGR_CDC_CHANNEL_DATA, data, len);
}

int cdc_async_poll_in(enum bsgr_cdc_channel channel, uint8_t *ch)
{
	if ((!cdc_is_ready) || (channel >= BSGR_CDC_CHANNEL_COUNT) || (ch == NULL)) {
		return -EINVAL;
	}

	return uart_poll_in(cdc_devices[channel], ch);
}
```

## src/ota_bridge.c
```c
#include <ctype.h>
#include <errno.h>
#include <stdio.h>
#include <stdlib.h>
#include <stdarg.h>
#include <string.h>

#include <zephyr/logging/log.h>
#include <zephyr/sys/util.h>

#include "app_ble.h"
#include "cdc_async.h"
#include "ota_bridge.h"

LOG_MODULE_REGISTER(central_ota_bridge, LOG_LEVEL_INF);

#define BSGR_OTA_CMD_MAX 96
#define BSGR_OTA_TARGET_MAX 31
#define BSGR_OTA_CHUNK_MAX 128

enum bsgr_ota_bridge_mode {
	BSGR_OTA_BRIDGE_MODE_COMMAND = 0,
	BSGR_OTA_BRIDGE_MODE_CHUNK,
};

struct bsgr_ota_bridge_state {
	enum bsgr_ota_bridge_mode mode;
	char cmd_buf[BSGR_OTA_CMD_MAX];
	size_t cmd_len;
	char target_name[BSGR_OTA_TARGET_MAX + 1];
	uint8_t chunk_buf[BSGR_OTA_CHUNK_MAX];
	size_t chunk_expected;
	size_t chunk_received;
	size_t upload_size;
	size_t upload_received;
	bool upload_active;
	char last_hash[BSGR_IMG_HASH_LEN];
	bool last_hash_valid;
};

static struct bsgr_ota_bridge_state bridge_state;

static void bridge_write_line(const char *fmt, ...)
{
	va_list args;
	char line[160];
	int len;

	va_start(args, fmt);
	len = vsnprintf(line, sizeof(line), fmt, args);
	va_end(args);

	if (len > 0) {
		(void)cdc_async_write_data((const uint8_t *)line,
					   MIN((size_t)len, sizeof(line) - 1U));
	}
}

static void hash_to_hex(const char *hash, char *hex, size_t hex_len)
{
	static const char digits[] = "0123456789abcdef";
	size_t i;

	if (hex_len < (BSGR_IMG_HASH_LEN * 2U + 1U)) {
		return;
	}

	for (i = 0; i < BSGR_IMG_HASH_LEN; ++i) {
		hex[(i * 2U)] = digits[((uint8_t)hash[i]) >> 4];
		hex[(i * 2U) + 1U] = digits[((uint8_t)hash[i]) & 0x0F];
	}

	hex[BSGR_IMG_HASH_LEN * 2U] = '\0';
}

static int bridge_list_images(void)
{
	struct bsgr_mcumgr_image_data images[4];
	struct bsgr_mcumgr_image_state state;
	size_t i;
	int err;
	char hash_hex[BSGR_IMG_HASH_LEN * 2U + 1U];

	err = app_ble_ota_read_images(&state, images, ARRAY_SIZE(images));
	if (err != 0) {
		return err;
	}

	bridge_write_line("OK LIST %d\r\n", state.image_list_length);
	for (i = 0; i < (size_t)state.image_list_length; ++i) {
		hash_to_hex(images[i].hash, hash_hex, sizeof(hash_hex));
		bridge_write_line("IMAGE slot=%u active=%u confirmed=%u pending=%u hash=%s version=%s\r\n",
				  images[i].slot_num,
				  images[i].flags.active ? 1 : 0,
				  images[i].flags.confirmed ? 1 : 0,
				  images[i].flags.pending ? 1 : 0,
				  hash_hex,
				  images[i].version);
	}

	return 0;
}

static int bridge_finish_upload(void)
{
	struct bsgr_mcumgr_image_data images[4];
	struct bsgr_mcumgr_image_state state;
	char hash_hex[BSGR_IMG_HASH_LEN * 2U + 1U];
	size_t i;
	int err;

	err = app_ble_ota_read_images(&state, images, ARRAY_SIZE(images));
	if (err != 0) {
		return err;
	}

	for (i = 0; i < (size_t)state.image_list_length; ++i) {
		if (images[i].slot_num != 0U) {
			memcpy(bridge_state.last_hash, images[i].hash, BSGR_IMG_HASH_LEN);
			bridge_state.last_hash_valid = true;
			break;
		}
	}

	if (!bridge_state.last_hash_valid) {
		return -ENOENT;
	}

	err = app_ble_ota_mark_test(bridge_state.last_hash);
	if (err != 0) {
		return err;
	}

	hash_to_hex(bridge_state.last_hash, hash_hex, sizeof(hash_hex));
	err = app_ble_ota_reset_target();
	if (err != 0) {
		return err;
	}

	bridge_state.upload_active = false;
	bridge_state.upload_size = 0U;
	bridge_state.upload_received = 0U;
	bridge_write_line("OK APPLY %s\r\n", hash_hex);
	return 0;
}

static int bridge_handle_command(const char *cmd)
{
	char target[BSGR_OTA_TARGET_MAX + 1];
	unsigned long size_ul;
	unsigned int chunk_len;
	int err;

	if (strncmp(cmd, "PING", 4) == 0) {
		bridge_write_line("OK PONG\r\n");
		return 0;
	}

	if (sscanf(cmd, "CONNECT %31s", target) == 1) {
		err = app_ble_ota_connect(target, K_SECONDS(15));
		if (err != 0) {
			bridge_write_line("ERR CONNECT %d\r\n", err);
			return err;
		}

		strncpy(bridge_state.target_name, target, sizeof(bridge_state.target_name) - 1U);
		bridge_write_line("OK CONNECT %s\r\n", target);
		return 0;
	}

	if (strcmp(cmd, "LIST") == 0) {
		err = bridge_list_images();
		if (err != 0) {
			bridge_write_line("ERR LIST %d\r\n", err);
		}
		return err;
	}

	if (sscanf(cmd, "BEGIN %31s %lu", target, &size_ul) == 2) {
		err = app_ble_ota_connect(target, K_SECONDS(15));
		if (err != 0) {
			bridge_write_line("ERR CONNECT %d\r\n", err);
			return err;
		}

		err = app_ble_ota_upload_start((size_t)size_ul);
		if (err != 0) {
			bridge_write_line("ERR BEGIN %d\r\n", err);
			return err;
		}

		memset(bridge_state.target_name, 0, sizeof(bridge_state.target_name));
		strncpy(bridge_state.target_name, target, sizeof(bridge_state.target_name) - 1U);
		bridge_state.upload_active = true;
		bridge_state.upload_size = (size_t)size_ul;
		bridge_state.upload_received = 0U;
		bridge_state.last_hash_valid = false;
		bridge_write_line("OK BEGIN %s %zu\r\n", bridge_state.target_name, bridge_state.upload_size);
		return 0;
	}

	if (sscanf(cmd, "CHUNK %u", &chunk_len) == 1) {
		if (!bridge_state.upload_active) {
			bridge_write_line("ERR STATE %d\r\n", -EINVAL);
			return -EINVAL;
		}

		if ((chunk_len == 0U) || (chunk_len > BSGR_OTA_CHUNK_MAX)) {
			bridge_write_line("ERR CHUNK %d\r\n", -EMSGSIZE);
			return -EMSGSIZE;
		}

		bridge_state.mode = BSGR_OTA_BRIDGE_MODE_CHUNK;
		bridge_state.chunk_expected = (size_t)chunk_len;
		bridge_state.chunk_received = 0U;
		return 0;
	}

	if (strcmp(cmd, "END") == 0) {
		err = bridge_finish_upload();
		if (err != 0) {
			bridge_write_line("ERR END %d\r\n", err);
		}
		return err;
	}

	if (strcmp(cmd, "REBOOT") == 0) {
		err = app_ble_ota_reset_target();
		if (err != 0) {
			bridge_write_line("ERR REBOOT %d\r\n", err);
			return err;
		}

		bridge_write_line("OK REBOOT %s\r\n",
				  bridge_state.target_name[0] != '\0' ?
				  bridge_state.target_name : "TARGET");
		return 0;
	}

	if (strcmp(cmd, "DISCONNECT") == 0) {
		app_ble_ota_disconnect();
		memset(&bridge_state, 0, sizeof(bridge_state));
		bridge_write_line("OK DISCONNECT\r\n");
		return 0;
	}

	bridge_write_line("ERR UNKNOWN\r\n");
	return -EINVAL;
}

static void bridge_process_chunk_byte(uint8_t ch)
{
	size_t remote_offset;
	int err;

	if (bridge_state.chunk_received < bridge_state.chunk_expected) {
		bridge_state.chunk_buf[bridge_state.chunk_received++] = ch;
	}

	if (bridge_state.chunk_received != bridge_state.chunk_expected) {
		return;
	}

	err = app_ble_ota_upload_chunk(bridge_state.chunk_buf, bridge_state.chunk_expected,
				       &remote_offset);
	if (err != 0) {
		bridge_write_line("ERR UPLOAD %d\r\n", err);
		bridge_state.upload_active = false;
	} else {
		bridge_state.upload_received += bridge_state.chunk_expected;
		bridge_write_line("OK CHUNK %zu/%zu off=%zu\r\n",
				  bridge_state.upload_received,
				  bridge_state.upload_size,
				  remote_offset);
	}

	bridge_state.mode = BSGR_OTA_BRIDGE_MODE_COMMAND;
	bridge_state.chunk_expected = 0U;
	bridge_state.chunk_received = 0U;
}

int ota_bridge_init(void)
{
	memset(&bridge_state, 0, sizeof(bridge_state));
	return 0;
}

void ota_bridge_process(void)
{
	uint8_t ch;

	while (cdc_async_poll_in(BSGR_CDC_CHANNEL_DATA, &ch) == 0) {
		if (bridge_state.mode == BSGR_OTA_BRIDGE_MODE_CHUNK) {
			bridge_process_chunk_byte(ch);
			continue;
		}

		if (ch == '\r') {
			continue;
		}

		if (ch == '\n') {
			bridge_state.cmd_buf[bridge_state.cmd_len] = '\0';
			if (bridge_state.cmd_len > 0U) {
				(void)bridge_handle_command(bridge_state.cmd_buf);
			}
			bridge_state.cmd_len = 0U;
			continue;
		}

		if (bridge_state.cmd_len < (sizeof(bridge_state.cmd_buf) - 1U)) {
			bridge_state.cmd_buf[bridge_state.cmd_len++] = (char)ch;
		}
	}
}
```

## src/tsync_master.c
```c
#include "tsync_master.h"

static struct bsgr_tsync_master_state g_tsync_master;

void tsync_master_init(void)
{
	g_tsync_master.epoch_ms = 0;
	g_tsync_master.session_id = 1U;
	g_tsync_master.request_id = 0U;
}

void tsync_master_set_epoch_ms(int64_t epoch_ms)
{
	g_tsync_master.epoch_ms = epoch_ms;
}

int64_t tsync_master_get_epoch_ms(void)
{
	return g_tsync_master.epoch_ms;
}

uint16_t tsync_master_next_request_id(void)
{
	return ++g_tsync_master.request_id;
}

uint16_t tsync_master_get_session_id(void)
{
	return g_tsync_master.session_id;
}

void tsync_master_fill_payload(struct bsgr_tsync_payload *payload, uint32_t reference_ticks)
{
	if (payload == NULL) {
		return;
	}

	payload->role = 0x01u;
	payload->reserved0 = 0U;
	payload->session_id = g_tsync_master.session_id;
	payload->host_time_offset_ms = (int32_t)g_tsync_master.epoch_ms;
	payload->reference_ticks = reference_ticks;
}
```

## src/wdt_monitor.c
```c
#include <zephyr/device.h>
#include <zephyr/drivers/watchdog.h>
#include <zephyr/logging/log.h>

#include "wdt_monitor.h"

LOG_MODULE_REGISTER(central_wdt_monitor, LOG_LEVEL_INF);

static const struct device *wdt_dev;
static int wdt_channel = -1;

int wdt_monitor_init(void)
{
#if defined(BSGR_CENTRAL_SAFE_BOOT) && (BSGR_CENTRAL_SAFE_BOOT == 1)
	LOG_WRN("Safe-boot mode: watchdog arming deferred");
	return 0;
#else
#if DT_NODE_EXISTS(DT_NODELABEL(wdt0))
	static const struct wdt_timeout_cfg timeout_cfg = {
		.window = {
			.min = 0U,
			.max = 4000U,
		},
		.callback = NULL,
		.flags = WDT_FLAG_RESET_SOC,
	};

	wdt_dev = DEVICE_DT_GET(DT_NODELABEL(wdt0));
	if (!device_is_ready(wdt_dev)) {
		wdt_dev = NULL;
		return 0;
	}

	wdt_channel = wdt_install_timeout(wdt_dev, &timeout_cfg);
	if (wdt_channel < 0) {
		wdt_dev = NULL;
		return 0;
	}

	if (wdt_setup(wdt_dev, 0U) != 0) {
		wdt_dev = NULL;
		wdt_channel = -1;
		return 0;
	}

	LOG_INF("Watchdog armed");
#else
	LOG_INF("Watchdog node not present, stub mode");
#endif
	return 0;
#endif
}

void wdt_monitor_feed(void)
{
	if ((wdt_dev == NULL) || (wdt_channel < 0)) {
		return;
	}

	(void)wdt_feed(wdt_dev, wdt_channel);
}
```
